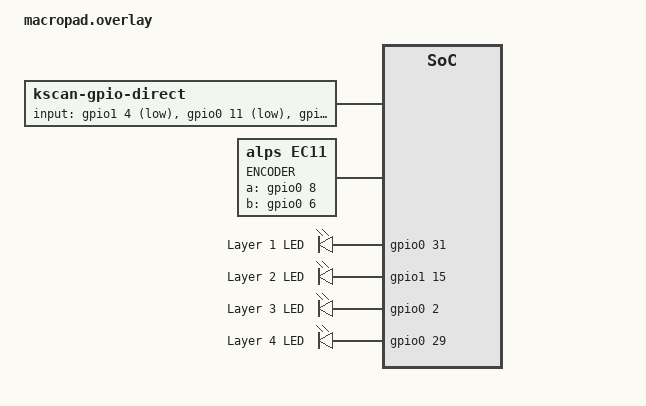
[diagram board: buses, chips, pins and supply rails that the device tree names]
#include <dt-bindings/gpio/gpio.h>

/ {
    chosen {
        zmk,kscan = &kscan0;
    };

    // 스위치 1~6번 및 노브 클릭 스위치
    kscan0: kscan_0 {
        compatible = "zmk,kscan-gpio-direct";
        label = "KSCAN";
        input-gpios
            = <&gpio1 4  (GPIO_ACTIVE_LOW | GPIO_PULL_UP)> // 1번 스위치 (P1.04)
            , <&gpio0 11 (GPIO_ACTIVE_LOW | GPIO_PULL_UP)> // 2번 스위치 (P0.11)
            , <&gpio1 0  (GPIO_ACTIVE_LOW | GPIO_PULL_UP)> // 3번 스위치 (P1.00)
            , <&gpio0 24 (GPIO_ACTIVE_LOW | GPIO_PULL_UP)> // 4번 스위치 (P0.24)
            , <&gpio0 22 (GPIO_ACTIVE_LOW | GPIO_PULL_UP)> // 5번 스위치 (P0.22)
            , <&gpio0 20 (GPIO_ACTIVE_LOW | GPIO_PULL_UP)> // 6번 스위치 (P0.20)
            , <&gpio0 17 (GPIO_ACTIVE_LOW | GPIO_PULL_UP)> // 노브 클릭 스위치 (P0.17)
            ;
    };

    // 로터리 엔코더 (회전 방향 반전: P0.08 <-> P0.06 교체)
    encoder: encoder {
        compatible = "alps,ec11";
        label = "ENCODER";
        a-gpios = <&gpio0 8 (GPIO_ACTIVE_HIGH | GPIO_PULL_UP)>; // P0.08
        b-gpios = <&gpio0 6 (GPIO_ACTIVE_HIGH | GPIO_PULL_UP)>; // P0.06
        steps = <80>;
        status = "okay";
    };

    sensors: sensors {
        compatible = "zmk,keymap-sensors";
        sensors = <&encoder>;
        triggers-per-rotation = <20>;
    };

    // LED 4개 핀 정의 (2번과 4번 핀 맞교환 완료)
    gpio_leds {
        compatible = "gpio-leds";
        led_0: led_0 {
            gpios = <&gpio0 31 GPIO_ACTIVE_HIGH>; // 1번 레이어 LED (P0.31 원래대로 복귀)
            label = "Layer 1 LED";
        };
        led_1: led_1 {
            gpios = <&gpio1 15 GPIO_ACTIVE_HIGH>; // 2번 레이어 LED (P1.15로 변경)
            label = "Layer 2 LED";
        };
        led_2: led_2 {
            gpios = <&gpio0 2  GPIO_ACTIVE_HIGH>; // 3번 레이어 LED (P0.02 원래대로 복귀)
            label = "Layer 3 LED";
        };
        led_3: led_3 {
            gpios = <&gpio0 29 GPIO_ACTIVE_HIGH>; // 4번 레이어 LED (P0.29로 변경)
            label = "Layer 4 LED";
        };
    };

    aliases {
        led0 = &led_0;
        led1 = &led_1;
        led2 = &led_2;
        led3 = &led_3;
    };
};
